# GAP8 register map
Vendor: GreenWaves Technologies SAS; Series: GAP8; File version: 1.3.1
CPU: other r1p0, little endian, MPU, no FPU, I-cache, DTCM, false interrupt priority bits
Registers are 32-bit, read-write, reset 0x0 unless marked. A register's access mark holds for its fields unless they carry their own. Offsets are from the block's base; [hi:lo] are bit positions; {n}, {i} and the like mark numbered series.

## cl_event_unit — Cluster event unit
Base 0x10200800
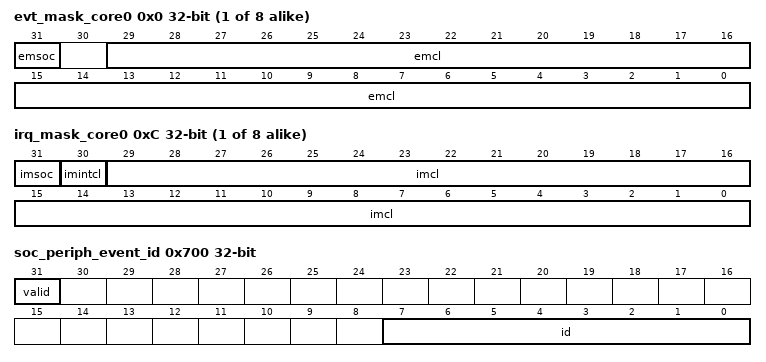
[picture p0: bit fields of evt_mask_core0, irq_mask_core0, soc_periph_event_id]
{0x0+0x40*i} evt_mask_core{i} (i=0..7) — Input event mask configuration register.
  [31] emsoc — Soc peripheral input event mask configuration bitfield: - EMSOC[i]=1'b0: Input event request i is masked - EMSOC[i]=1'b1: Input event request i is not masked
  [29:0] emcl — Cluster internal input event mask configuration bitfield: - EMCL[i]=1'b0: Input event request i is masked - EMCL[i]=1'b1: Input event request i is not masked
{0x4+0x40*i} evt_mask_and_core{i} wo (i=0..7) — Input event mask update command register with bitwise AND operation.
  [31:0] ema — Input event mask configuration bitfield update with bitwise AND operation. It allows clearing EMCL[i], EMINTCL[i] or EMSOC[i] if EMA[i]=1'b1.
{0x8+0x40*i} evt_mask_or_core{i} wo (i=0..7) — Input event mask update command register with bitwise OR operation.
  [31:0] emo — Input event mask configuration bitfield update with bitwise OR operation. It allows setting EMCL[i], EMINTCL[i] or EMSOC[i] if EMO[i]=1'b1.
{0xC+0x40*i} irq_mask_core{i} (i=0..7) — Interrupt request mask configuration register.
  [31] imsoc — Soc peripheral interrupt request mask configuration bitfield: - bit[i]=1'b0: Interrupt request i is masked - bit[i]=1'b1: Interrupt request i is not masked
  [30] imintcl — Inter-cluster interrupt request mask configuration bitfield: - bit[i]=1'b0: Interrupt request i is masked - bit[i]=1'b1: Interrupt request i is not masked
  [29:0] imcl — Cluster internal interrupt request mask configuration bitfield: - bit[i]=1'b0: Interrupt request i is masked - bit[i]=1'b1: Interrupt request i is not masked
{0x10+0x40*i} irq_mask_and_core{i} wo (i=0..7) — Interrupt request mask update command register with bitwise AND operation.
  [31:0] ima — Interrupt request mask configuration bitfield update with bitwise AND operation. It allows clearing IMCL[i], IMINTCL[i] or IMSOC[i] if IMA[i]=1'b1.
{0x14+0x40*i} irq_mask_or_core{i} wo (i=0..7) — Interrupt request mask update command register with bitwise OR operation.
  [31:0] imo — Interrupt request mask configuration bitfield update with bitwise OR operation. It allows setting IMCL[i], IMINTCL[i] or IMSOC[i] if IMO[i]=1'b1.
{0x18+0x40*i} clock_status_core{i} ro (i=0..7) — Cluster cores clock status register.
  [0] cs — Cluster core clock status bitfield
    on read: 0=Cluster core clocked is gated; 1=Cluster core clocked is running
{0x1C+0x40*i} event_buffer_core{i} ro (i=0..7) — Pending input events status register.
  [31:0] eb — Pending input events status bitfield. EB[i]=1'b1: one or more input event i request are pending.
{0x20+0x40*i} event_buffer_masked_core{i} ro (i=0..7) — Pending input events status register with EVT_MASK applied.
  [31:0] ebm — Pending input events status bitfield with EVT_MASK applied. EBM[i]=1'b1: one or more input event i request are pending.
{0x24+0x40*i} event_buffer_irq_masked_core{i} ro (i=0..7) — Pending input events status register with IRQ_MASK applied.
  [31:0] ibm — Pending input events status bitfield with IRQ_MASK applied. IBM[i]=1'b1: one or more input events i are pending.
{0x28+0x40*i} event_buffer_clear_core{i} wo (i=0..7) — Pending input events status clear command register.
  [31:0] ebc — Pending input events status clear command bitfield. It allows clearing EB[i] if EBC[i]=1'b1.
{0x2C+0x40*i} sw_event_mask_core{i} (i=0..7) — Software events cluster cores destination mask configuration register.
  [7:0] swem — Software events mask configuration bitfield: - bit[i]=1'b0: software events are masked for CL_CORE[i] - bit[i]=1'b1: software events are not masked for CL_CORE[i]
{0x30+0x40*i} sw_event_mask_and_core{i} wo (i=0..7) — Software events cluster cores destination mask update command register with bitwise AND operation.
  [7:0] swema — Software event mask configuration bitfield update with bitwise AND operation. It allows clearing SWEM[i] if SWEMA[i]=1'b1.
{0x34+0x40*i} sw_event_mask_or_core{i} wo (i=0..7) — Software events cluster cores destination mask update command register with bitwise OR operation.
  [7:0] swemo — Software event mask configuration bitfield update with bitwise OR operation. It allows setting SWEM[i] if SWEMO[i]=1'b1.
{0x400+0x20*i} hw_barrier_{i}_trig_mask (i=0..7) — Cluster hardware barrier {i} trigger mask configuration register.
  [7:0] hb{i}tm — Trigger mask for hardware barrier {i} bitfield. Hardware barrier {i} will be triggered only if for all HB{i}TM[i] = 1'b1, HW_BARRIER_{i}_STATUS.HB{i}S[i]=1'b1. HB{i}TM=0 means that hardware barrier {i} is disabled.
{0x404+0x20*i} hw_barrier_{i}_status ro (i=0..7) — Cluster hardware barrier {i} status register.
  [7:0] hbs — Current status of hardware barrier {i} bitfield. HBS[i]=1'b1 means that cluster core i has triggered hardware barrier {i}. It is cleared when HBS matches HW_BARRIER_{i}_TRIG_MASK.HB{i}TM.
{0x408+0x20*i} hw_barrier_{i}_status_sum ro (i=0..7) — Cluster hardware barrier summary status register.
  [7:0] hbss — Current status of hardware barrier {i}. HBSS[i] represents a summary of the barrier status for core i.
{0x40C+0x20*i} hw_barrier_{i}_target_mask (i=0..7) — Cluster hardware barrier {i} target mask configuration register.
  [7:0] hbtam — Cluster hardware barrier {i} target mask configuration bitfield. HBATM[i]=1'b1 means that cluster core i will receive hardware barrier {i} event when HW_BARRIER_{i}_STATUS will match HW_BARRIER_{i}_TRIG_MASK.
{0x410+0x20*i} hw_barrier_{i}_trig wo (i=0..7) — Cluster hardware barrier {i} trigger command register.
  [7:0] t — Sets HW_BARRIER_{i}_STATUS.HBS[i] to 1'b1 when T[i]=1'b1.
{0x600+4i} sw_event_{i}_trig wo (i=0..7) — Cluster Software event {i} trigger command register.
  [7:0] sw{i}t — Triggers software event {i} for cluster core i if SW{i}T[i]=1'b1.
0x700 soc_periph_event_id ro — Cluster SoC peripheral event ID status register.
  [31] valid — Validity bit of SOC_PERIPH_EVENT_ID.ID bitfield.
  [7:0] id — Oldest SoC peripheral event ID status bitfield.
